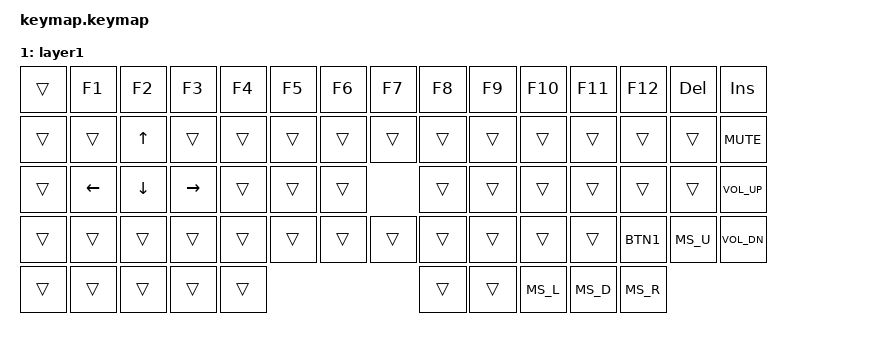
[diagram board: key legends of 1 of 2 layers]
/ {
    keymap {
        compatible = "zmk,keymap";

        default_layer {
            bindings = <
&kp ESC  &kp N1   &kp N2   &kp N3   &kp N4   &kp N5   &kp N6   &kp N7   &kp N8   &kp N9   &kp N0   &kp MINUS &kp EQUAL &kp BSPC  &kp GRAVE
&kp TAB  &kp Q    &kp W    &kp E    &kp R    &kp T    &kp Y    &kp U    &kp I    &kp O    &kp P    &kp LBKT  &kp RBKT  &kp BSLH  &kp DEL
&kp CAPS &kp A    &kp S    &kp D    &kp F    &kp G    &kp H    &kp J    &kp K    &kp L    &kp SEMI  &kp SQT   &kp RET   &kp PG_UP
&kp LSHFT&kp Z    &kp X    &kp C    &kp V    &kp B    &kp N    &kp M    &kp COMMA&kp DOT  &kp FSLH  &kp RSHFT &kp UP    &kp PG_DN
&kp LCTRL&kp LGUI &kp LALT                &kp SPACE           &kp RALT  &mo 1   &kp RCTRL &kp LEFT  &kp DOWN  &kp RIGHT
            >;
        };

        layer1 {
            bindings = <
&trans &kp F1 &kp F2 &kp F3 &kp F4 &kp F5 &kp F6 &kp F7 &kp F8 &kp F9 &kp F10 &kp F11 &kp F12 &kp DEL &kp INS
&trans &trans &kp UP &trans &trans &trans &trans &trans &trans &trans &trans &trans &trans &trans &kp C_MUTE
&trans &kp LEFT &kp DOWN &kp RIGHT &trans &trans &trans &trans &trans &trans &trans &trans &trans &kp C_VOL_UP
&trans &trans &trans &trans &trans &trans &trans &trans &trans &trans &trans &trans &kp BTN1 &kp MS_U &kp C_VOL_DN
&trans &trans &trans           &trans           &trans &trans &trans &kp MS_L &kp MS_D &kp MS_R
            >;
        };
    };
};
